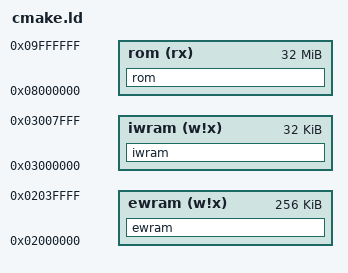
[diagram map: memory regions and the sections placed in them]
ENTRY(__start)

gNumMusicPlayers = 0x20;
gMaxLines = 0;

MEMORY {
    ewram (w!x) : ORIGIN = 0x02000000, LENGTH = 256K
    iwram (w!x) : ORIGIN = 0x03000000, LENGTH = 32K
    rom (rx) : ORIGIN = 0x08000000, LENGTH = 32M
}

SECTIONS {
    ewram (NOLOAD) : ALIGN(4) {
        . = 0x00000006; gUnk_02000006 = .;
        . = 0x00000010; gUnk_02000010 = .;
        . = 0x00000020; gUnk_02000020 = .;
        . = 0x00000030; gUnk_02000030 = .;
        . = 0x00000040; gUnk_02000040 = .;
        . = 0x00000050; gTextBox = .;
        . = 0x0000005C; gUnk_0200005C = .;
        . = 0x00000070; gUnk_02000070 = .;
        . = 0x00000080; gMenu = .;
        . = 0x00000080; gIntroState = .;
        . = 0x00000080; gChooseFileState = .;
        . = 0x00000090; gUnk_02000090 = .;
        . = 0x000000B0; gUnk_020000B0 = .;
        . = 0x000000C0; gUnk_020000C0 = .;
        . = 0x00000CC0; gUnk_02000CC0 = .;
        . = 0x00000D00; gUnk_02000D00 = .;
        . = 0x00001A00; gUnk_02001A00 = .;
        . = 0x00001A3C; gUnk_02001A3C = .;
        . = 0x00001A40; gBG3Buffer = .;
        . = 0x00001B40; gUnk_02001B40 = .;
        . = 0x00002A40; gSave = .;
        . = 0x00002AA0; gUnk_02002AA0 = .;
        . = 0x00002AC0; gUnk_02002AC0 = .;
        . = 0x00002AC8; gUnk_02002AC8 = .;
        . = 0x00002AE8; gStats = .;
        . = 0x00002B0E; gUnk_02002B0E = .;
        . = 0x00002B32; gUnk_02002B32 = .;
        . = 0x00002B54; gUnk_02002B54 = .;
        . = 0x00002B58; gUnk_02002B58 = .;
        . = 0x00002B6B; gUnk_02002B6B = .;
        . = 0x00002C01; gUnk_02002C01 = .;
        . = 0x00002C81; gUnk_02002C81 = .;
        . = 0x00002C8E; gUnk_02002C8E = .;
        . = 0x00002C9C; gGlobalFlags = .;
        . = 0x00002E9C; gUnk_02002E9C = .;
        . = 0x00002ECC; gUnk_02002ECC = .;
        . = 0x00002F00; gMapDataTopSpecial = .;
        . = 0x00006F00; gUnk_02006F00 = .;
        . = 0x0000AF00; gUnk_0200AF00 = .;
        . = 0x0000AF13; gUnk_0200AF13 = .;
        . = 0x0000AF34; gUnk_0200AF34 = .;
        . = 0x0000B240; gUnk_0200B240 = .;
        . = 0x0000B640; gUnk_0200B640 = .;
        . = 0x0000B644; gUsedPalettes = .;
        . = 0x0000B650; gUnk_0200B650 = .;
        . = 0x0000B654; gMapDataTop = .;
        . = 0x0000D654; gUnk_0200D654 = .;
        . = 0x0000E654; gUnk_0200E654 = .;
        . = 0x00010654; gMetatileTypesTop = .;
        . = 0x00011654; gUnk_02011654 = .;
        . = 0x00012654; gMetatilesTop = .;
        . = 0x00016654; gUnk_02016654 = .;
        . = 0x00017654; gUnk_02017654 = .;
        . = 0x00017660; gUnk_02017660 = .;
        . = 0x000176A0; gPaletteBuffer = .;
        . = 0x000176E0; gUnk_020176E0 = .;
        . = 0x00017700; gUnk_02017700 = .;
        . = 0x00017830; gUnk_02017830 = .;
        . = 0x000178E0; gUnk_020178E0 = .;
        . = 0x00017AA0; gUnk_02017AA0 = .;
        . = 0x00017BA0; gUnk_02017BA0 = .;
        . = 0x00018EA0; gUnk_02018EA0 = .;
        . = 0x00018EB0; gUnk_02018EB0 = .;
        . = 0x00018EE0; gUnk_02018EE0 = .;
        . = 0x00019EE0; gUnk_02019EE0 = .;
        . = 0x00019F6C; gUnk_02019F6C = .;
        . = 0x0001AEE0; gUnk_0201AEE0 = .;
        . = 0x00021EE0; gSoundPlayingInfo = .;
        . = 0x00021F00; gUnk_02021F00 = .;
        . = 0x00021F20; gUnk_02021F20 = .;
        . = 0x00021F30; gBG1Buffer = .;
        . = 0x00021F70; gUnk_02021F70 = .;
        . = 0x00022030; gUnk_02022030 = .;
        . = 0x00022130; gUnk_02022130 = .;
        . = 0x00022730; gUnk_02022730 = .;
        . = 0x00022740; gUnk_02022740 = .;
        . = 0x00022750; gPlayerScriptExecutionContext = .;
        . = 0x00022780; gUnk_02022780 = .;
        . = 0x000227DC; gUnk_020227DC = .;
        . = 0x000227E8; gUnk_020227E8 = .;
        . = 0x000227F0; gUnk_020227F0 = .;
        . = 0x000227F8; gUnk_020227F8 = .;
        . = 0x00022800; gUnk_02022800 = .;
        . = 0x0002281E; gUnk_0202281E = .;
        . = 0x00022830; gUnk_02022830 = .;
        . = 0x00024030; gUnk_02024030 = .;
        . = 0x00024048; gUnk_02024048 = .;
        . = 0x00024050; gUnk_02024050 = .;
        . = 0x00024090; gUnk_02024090 = .;
        . = 0x00024490; gUnk_02024490 = .;
        . = 0x00024494; gUnk_02024494 = .;
        . = 0x000246B0; gUnk_020246B0 = .;
        . = 0x00025EB0; gUnk_02025EB0 = .;
        . = 0x00025EB4; gMapDataBottom = .;
        . = 0x00027EB4; gUnk_02027EB4 = .;
        . = 0x00028EB4; gUnk_02028EB4 = .;
        . = 0x0002AEB4; gMetatileTypesBottom = .;
        . = 0x0002BEB4; gUnk_0202BEB4 = .;
        . = 0x0002CEB4; gMetatilesBottom = .;
        . = 0x00030EB4; gUnk_02030EB4 = .;
        . = 0x00031EC0; gUnk_02031EC0 = .;
        . = 0x00032EC0; gUnk_02032EC0 = .;
        . = 0x00032EDC; gUnk_02032EDC = .;
        . = 0x00032F14; gUnk_02032F14 = .;
        . = 0x00033280; gActiveScriptInfo = .;
        . = 0x00033290; gUnk_02033290 = .;
        . = 0x00033A90; gArea = .;
        . = 0x00033AB8; gUnk_02033AB8 = .;
        . = 0x00033ACC; gUnk_02033ACC = .;
        . = 0x000342CC; gUnk_020342CC = .;
        . = 0x000342F8; gUnk_020342F8 = .;
        . = 0x00034330; gUnk_02034330 = .;
        . = 0x00034350; gRoomVars = .;
        . = 0x00034364; gRoomFlags = .;
        . = 0x00034398; gUnk_02034398 = .;
        . = 0x00034480; gUnk_02034480 = .;
        . = 0x00034490; gUnk_02034490 = .;
        . = 0x00034492; gUnk_02034492 = .;
        . = 0x000344A0; gUnk_020344A0 = .;
        . = 0x000344B0; gBG2Buffer = .;
        . = 0x000344F0; gUnk_020344F0 = .;
        . = 0x00034CB0; gBG0Buffer = .;
        . = 0x00034CB2; gUnk_02034CB2 = .;
        . = 0x00034CF0; gUnk_02034CF0 = .;
        . = 0x00034D30; gUnk_02034D30 = .;
        . = 0x00034DF0; gUnk_02034DF0 = .;
        . = 0x000350E2; gUnk_020350E2 = .;
        . = 0x000350F0; gUnk_020350F0 = .;
        . = 0x00035160; gUnk_02035160 = .;
        . = 0x000354B0; gUnk_020354B0 = .;
        . = 0x000354B4; gManagerCount = .;
        . = 0x000354C0; gUnk_020354C0 = .;
        . = 0x0003553E; gUnk_0203553E = .;
        . = 0x00035540; gzHeap = .;
        . = 0x00035542; gUnk_02035542 = .;
        . = 0x00036540; gUnk_02036540 = .;
        . = 0x00036570; gScriptExecutionContextArray = .;
        . = 0x000369F0; gUnk_020369F0 = .;
        . = 0x00036A38; gUnk_02036A38 = .;
        . = 0x00036A40; gUnk_02036A40 = .;
        . = 0x00036A50; gEEPROMConfig = .;
        . = 0x00036A58; gUnk_02036A58 = .;
        . = 0x00036AD8; gUnk_02036AD8 = .;
        . = 0x00036BB8; gUnk_02036BB8 = .;
        . = 0x00036BC0; gMPlayTracks = .;
        . = 0x00038560; gUnk_02038560 = .;
        . = 0x00040000;
    } >ewram

    iwram (NOLOAD) : ALIGN(4) {
        . = 0x00000000; gUnk_03000000 = .;
        . = 0x00000020; gUnk_03000020 = .;
        . = 0x00000420; gUnk_03000420 = .;
        . = 0x00000B80; gUnk_03000B80 = .;
        . = 0x00000BD4; gUnk_03000BD4 = .;
        . = 0x00000BF0; gRoomControls = .;
        . = 0x00000BF6; gUnk_03000BF6 = .;
        . = 0x00000BF8; gUnk_03000BF8 = .;
        . = 0x00000C24; gUnk_03000C24 = .;
        . = 0x00000C30; gUnk_03000C30 = .;
        . = 0x00000E10; gUnk_03000E10 = .;
        . = 0x00000F50; gScreen = .;
        . = 0x00000F58; gBG0Settings = .;
        . = 0x00000F64; gBG1Settings = .;
        . = 0x00000F70; gBGAffSettings = .;
        . = 0x00000F88; gBgControls = .;
        . = 0x00000FBC; gUnk_03000FBC = .;
        . = 0x00000FD0; gFadeControl = .;
        . = 0x00000FF0; gInput = .;
        . = 0x00001000; gMain = .;
        . = 0x00001010; gOamCmd = .;
        . = 0x00001020; gUnk_03001020 = .;
        . = 0x000010A0; gScreenTransition = .;
        . = 0x000010AC; gUnk_030010AC = .;
        . = 0x000010D8; gUnk_030010D8 = .;
        . = 0x000010EC; gUnk_030010EC = .;
        . = 0x0000110C; gUnk_0300110C = .;
        . = 0x00001150; gRand = .;
        . = 0x00001160; gPlayerEntity = .;
        . = 0x00001198; gUnk_03001198 = .;
        . = 0x000011E8; gUnk_030011E8 = .;
        . = 0x000015A0; gUnk_030015A0 = .;
        . = 0x00003BE0; gUnk_03003BE0 = .;
        . = 0x00003C70; gUnk_03003C70 = .;
        . = 0x00003D68; gUnk_03003D68 = .;
        . = 0x00003D70; gEntityLists = .;
        . = 0x00003D80; gUnk_03003D80 = .;
        . = 0x00003D90; gUnk_03003D90 = .;
        . = 0x00003DA0; gUnk_03003DA0 = .;
        . = 0x00003DA8; gUnk_03003DA8 = .;
        . = 0x00003DB0; gUnk_03003DB0 = .;
        . = 0x00003DB8; gHitboxCount = .;
        . = 0x00003DBC; gEntCount = .;
        . = 0x00003DC0; gUnk_03003DC0 = .;
        . = 0x00003DD0; gUnk_03003DD0 = .;
        . = 0x00003DE0; gUnk_03003DE0 = .;
        . = 0x00003DE4; gUnk_03003DE4 = .;
        . = 0x00003DF0; gUnk_03003DF0 = .;
        . = 0x00003DF8; gUnk_03003DF8 = .;
        . = 0x00003F80; gPlayerState = .;
        . = 0x00003FC0; gUnk_03003FC0 = .;
        . = 0x00004010; gUnk_03004010 = .;
        . = 0x00004020; gUnk_03004020 = .;
        . = 0x00004030; gUnk_03004030 = .;
        . = 0x00004040; gUnk_03004040 = .;
        . = 0x0000404C; SoundMainRAM_Buffer = .;
        . = 0x0000404D; gUnk_0300404D = .;
        . = 0x000043D0; gSoundInfo = .;
        . = 0x00004D50; gMPlayJumpTable = .;
        . = 0x00004D54; gUnk_03004D54 = .;
        . = 0x00004DD8; gUnk_03004DD8 = .;
        . = 0x00004DDC; gUnk_03004DDC = .;
        . = 0x00004DE0; gCgbChans = .;
        . = 0x00004EE0; gMPlayInfos = .;
        . = 0x000055E0; gMPlayMemAccArea = .;
        . = 0x000055F0; gMPlayInfos2 = .;
        . = 0x000056F0; gUnk_030056F0 = .;
        . = 0x000056F1; gUnk_030056F1 = .;
        . = 0x00005740; gUnk_03005740 = .;
        . = 0x0000574C; gUnk_0300574C = .;
        . = 0x00005760; gUnk_03005760 = .;
        . = 0x00005770; gUnk_03005770 = .;
        . = 0x00005778; gUnk_03005778 = .;
        . = 0x00005780; gUnk_03005780 = .;
        . = 0x0000579C; gUnk_0300579C = .;
        . = 0x000057A8; gUnk_030057A8 = .;
        . = 0x000057BC; gUnk_030057BC = .;
        . = 0x000057CC; gUnk_030057CC = .;
        . = 0x000057D4; gUnk_030057D4 = .;
        . = 0x00005800; gUnk_03005800 = .;
        . = 0x0000581C; gUnk_0300581C = .;
        . = 0x00005828; gUnk_03005828 = .;
        . = 0x0000583C; gUnk_0300583C = .;
        . = 0x0000584C; gUnk_0300584C = .;
        . = 0x00005854; gUnk_03005854 = .;
        . = 0x00005864; gUnk_03005864 = .;
        . = 0x00005880; gUnk_03005880 = .;
        . = 0x0000588C; gUnk_0300588C = .;
        . = 0x000058A0; gUnk_030058A0 = .;
        . = 0x000058B0; gUnk_030058B0 = .;
        . = 0x000058B8; gUnk_030058B8 = .;
        . = 0x000058C8; gUnk_030058C8 = .;
        . = 0x000058DC; gUnk_030058DC = .;
        . = 0x000058F8; gUnk_030058F8 = .;
        . = 0x00005918; gUnk_03005918 = .;
        . = 0x000059F0; gDoCollision = .;
        . = 0x00005CA4; gUnk_03005CA4 = .;
        . = 0x00005CD0; gUnk_03005CD0 = .;
        . = 0x00005CFC; gUnk_03005CFC = .;
        . = 0x00005D18; gUnk_03005D18 = .;
        . = 0x00005D24; gUnk_03005D24 = .;
        . = 0x00005D58; gUnk_03005D58 = .;
        . = 0x00005D5C; gUnk_03005D5C = .;
        . = 0x00005D90; IntrMain = .;
        . = 0x00005E60; gUnk_03005E60 = .;
        . = 0x00005E98; gUnk_03005E98 = .;
        . = 0x00005F24; _EntUpdate = .;
        . = 0x00005F40; gUnk_03005F40 = .;
        . = 0x00005FBC; gUnk_03005FBC = .;
        . = 0x00005FF0; gUnk_03005FF0 = .;
        . = 0x000060F0; gUnk_030060F0 = .;
        . = 0x00006164; gUnk_03006164 = .;
        . = 0x00006580; gUnk_03006580 = .;
        . = 0x0000659C; gUnk_0300659C = .;
        . = 0x000067E4; gUnk_030067E4 = .;
        . = 0x000068CC; gUnk_030068CC = .;
        . = 0x0000694C; gUnk_0300694C = .;
        . = 0x0000695C; gUnk_0300695C = .;
        . = 0x00007F00; gUnk_03007F00 = .;
        . = 0x00007FA0; gUnk_03007FA0 = .;
        . = 0x00007FFA; gUnk_03007FFA = .;
        . = 0x00008000;
    } >iwram

    rom : ALIGN(2) {

        /* handwritten assembly */
        asm/crt0.s.obj(.text);
        asm/code_08000108.s.obj(.text);
        data/data_08000360.s.obj(.rodata);
        asm/code_08000E44.s.obj(.text);
        asm/libgcc.s.obj(.text);
        asm/code_08000F10.s.obj(.text);
        data/data_08000F54.s.obj(.rodata);
        asm/code_080011C4.s.obj(.text);
        data/data_080029B4.s.obj(.rodata);
        asm/code_08003FC4.s.obj(.text);
        asm/code_080043E8.s.obj(.text);
        data/data_08007DF4.s.obj(.rodata);
        asm/code_0800857C.s.obj(.text);
        /* scripts */
        data/scripts.s.obj(.text);
        asm/code_08016984.s.obj(.text);
        asm/sub_08016AE4.s.obj(.text);


        /* C source compiled with interworking */
        asm/code_08016B30.s.obj(.text);
        asm/updateBackgroundRegisters.s.obj(.text);
        src/arm_proxy.c.obj(.text);
        asm/code_08016DF8.s.obj(.text);
        /* C source compiled without interworking */
        asm/code_08018500.s.obj(.text);
        src/code_08018C58.c.obj(.text);
        src/playerItem/playerItem11.c.obj(.text);
        asm/playerItem11.s.obj(.text);
        src/playerItem/playerItemBow.c.obj(.text);
        asm/playerItem/playerItemBow.s.obj(.text);
        asm/playerItem/playerItemSwordBeam.s.obj(.text);
        asm/code_0801967C.s.obj(.text);
        asm/playerItem/playerItemBomb.s.obj(.text);
        asm/playerItem/playerItem3.s.obj(.text);
        asm/playerItem/playerItemC.s.obj(.text);
        asm/playerItem/playerItemSwordSpin.s.obj(.text);
        asm/playerItemCellOverwriteSet.s.obj(.text);
        asm/code_0801C1D4.s.obj(.text);
        asm/drawUI.s.obj(.text);
        asm/code_0801C370.s.obj(.text);
        asm/drawRupees.s.obj(.text);
        asm/code_0801C5E0.s.obj(.text);
        asm/drawHealth.s.obj(.text);
        asm/sub_0801C824.s.obj(.text);
        asm/code_0801C85C.s.obj(.text);
        src/ezloNag.c.obj(.text);
        asm/code_0801CEC0.s.obj(.text);
        src/utils.c.obj(.text);
        asm/code_0801D79C.s.obj(.text);
        /* enemies */
        src/enemy/octorok.c.obj(.text);
        src/enemy/chuchu.c.obj(.text);
        src/enemy/leever.c.obj(.text);
        src/enemy/peahat.c.obj(.text);
        src/enemy/rollobite.c.obj(.text);
        src/enemy/darkNut.c.obj(.text);
        src/enemy/hangingSeed.c.obj(.text);
        src/enemy/beetle.c.obj(.text);
        src/enemy/keese.c.obj(.text);
        src/enemy/doorMimic.c.obj(.text);
        src/enemy/rockChuchu.c.obj(.text);
        src/enemy/spinyChuchu.c.obj(.text);
        src/enemy/cuccoChickAggr.c.obj(.text);
        src/enemy/moldorm.c.obj(.text);
        src/enemy/enemyE.c.obj(.text);
        src/enemy/moldworm.c.obj(.text);
        src/enemy/sluggula.c.obj(.text);
        src/enemy/pesto.c.obj(.text);
        src/enemy/puffstool.c.obj(.text);
        src/enemy/chuchuBoss.c.obj(.text);
        asm/chuchuBoss.s.obj(.text);
        src/enemy/likeLike.c.obj(.text);
        src/enemy/spearMoblin.c.obj(.text);
        src/enemy/businessScrub.c.obj(.text);
        src/enemy/rupeeLike.c.obj(.text);
        src/enemy/madderpillar.c.obj(.text);
        src/enemy/waterDrop.c.obj(.text);
        src/enemy/wallMaster.c.obj(.text);
        src/enemy/bombPeahat.c.obj(.text);
        src/enemy/spark.c.obj(.text);
        src/enemy/chaser.c.obj(.text);
        src/enemy/spikedBeetle.c.obj(.text);
        src/enemy/sensorBladeTrap.c.obj(.text);
        src/enemy/helmasaur.c.obj(.text);
        src/enemy/fallingBoulder.c.obj(.text);
        src/enemy/bobomb.c.obj(.text);
        src/enemy/wallMaster2.c.obj(.text);
        asm/gleerok.s.obj(.text);
        asm/vaatiEyesMacro.s.obj(.text);
        src/enemy/tektite.c.obj(.text);
        asm/wizzrobeWind.s.obj(.text);
        asm/wizzrobeFire.s.obj(.text);
        asm/wizzrobeIce.s.obj(.text);
        src/code_080300AC.c.obj(.text); /* ??? */
        asm/code_080300AC.s.obj(.text); /* ??? */
        asm/armos.s.obj(.text);
        asm/eyegore.s.obj(.text);
        src/enemy/rope.c.obj(.text);
        src/enemy/smallPesto.c.obj(.text);
        src/enemy/acroBandits.c.obj(.text);
        src/enemy/bladeTrap.c.obj(.text);
        src/enemy/keaton.c.obj(.text);
        asm/crow.s.obj(.text);
        asm/mulldozer.s.obj(.text);
        asm/bombarossa.s.obj(.text);
        src/enemy/wisp.c.obj(.text);
        asm/spinyBeetle.s.obj(.text);
        asm/mazaalHead.s.obj(.text);
        asm/mazaalMacro.s.obj(.text);
        asm/mazaalHand.s.obj(.text);
        asm/octorokBoss.s.obj(.text);
        asm/flyingPot.s.obj(.text);
        src/enemy/gibdo.c.obj(.text);
        asm/octorokGolden.s.obj(.text);
        src/enemy/tektiteGolden.c.obj(.text);
        src/enemy/ropeGolden.c.obj(.text);
        asm/cloudPiranha.s.obj(.text);
        asm/scissorsBeetle.s.obj(.text);
        asm/cuccoAggr.s.obj(.text);
        asm/stalfos.s.obj(.text);
        asm/flyingSkull.s.obj(.text);
        asm/mazaalBracelet.s.obj(.text);
        asm/takkuri.s.obj(.text);
        src/enemy/bowMoblin.c.obj(.text);
        asm/bowMoblin.s.obj(.text);
        src/enemy/lakitu.c.obj(.text);
        src/enemy/lakituCloud.c.obj(.text);
        asm/enemy49.s.obj(.text);
        asm/vaatiRebornEnemy.s.obj(.text);
        asm/vaatiProjectile.s.obj(.text);
        asm/ballChainSoldier.s.obj(.text);
        src/enemy/enemy4D.c.obj(.text);
        asm/enemy4D.s.obj(.text);
        asm/ghini.s.obj(.text);
        asm/vaatiTransfigured.s.obj(.text);
        asm/enemy50.s.obj(.text);
        asm/vaatiWrath.s.obj(.text);
        asm/vaatiArm.s.obj(.text);
        asm/dust.s.obj(.text);
        src/enemy/vaatiBall.c.obj(.text);
        src/enemy/slime.c.obj(.text);
        asm/sub_080451CC.s.obj(.text);
        src/enemy/miniSlime.c.obj(.text);
        src/enemy/fireballGuy.c.obj(.text);
        src/enemy/miniFireballGuy.c.obj(.text);
        asm/enemy5A.s.obj(.text);
        asm/businessScrubPrologue.s.obj(.text);
        asm/gyorgFemale.s.obj(.text);
        src/enemy/gyorgMale.c.obj(.text);
        asm/curtain.s.obj(.text);
        asm/enemy5F.s.obj(.text);
        asm/gyorgChild.s.obj(.text);
        asm/gyorgFemaleEye.s.obj(.text);
        asm/enemy62.s.obj(.text);
        asm/gyorgFemaleMouth.s.obj(.text);
        asm/enemy64.s.obj(.text);
        src/enemy/treeItem.c.obj(.text);
        asm/enemy66.s.obj(.text);
        /* END enemies */
        src/code_08049CD4.c.obj(.text);
        asm/code_08049D30.s.obj(.text);
        asm/sub_0804AA30.s.obj(.text);
        src/createEnemy.c.obj(.text);
        src/code_0804AA84.c.obj(.text);
        asm/code_0804AA84.s.obj(.text);
        src/loadRoomEntityList.c.obj(.text);
        asm/loadRoomEntity.s.obj(.text);
        asm/code_0804AEB0.s.obj(.text);
        src/loadRoom.c.obj(.text);
        asm/code_0804B058.s.obj(.text);
        src/room.c.obj(.text);
        asm/code_0804B9F8.s.obj(.text);
        src/sub_08050008.c.obj(.text);
        src/fade.c.obj(.text);
        asm/code_08050038.s.obj(.text);
        src/fileScreen.c.obj(.text);
        asm/fileScreen.s.obj(.text);
        src/game.c.obj(.text);
        asm/code_080526F8.s.obj(.text);
        asm/modBombs.s.obj(.text);
        asm/modArrows.s.obj(.text);
        src/code_0805436C.c.obj(.text);
        asm/code_0805436C.s.obj(.text);
        asm/playerItem/playerItemLantern.s.obj(.text);
        asm/code_08054C04.s.obj(.text);
        src/sub_08055E08.c.obj(.text);
        src/main.c.obj(.text);
        src/textbox.c.obj(.text);
        asm/code_08056418.s.obj(.text);
        src/manager/manager1.c.obj(.text);
        asm/manager1.s.obj(.text);
        src/manager/manager2.c.obj(.text);
        asm/manager2.s.obj(.text);
        src/manager/manager3.c.obj(.text);
        src/manager/manager4.c.obj(.text);
        src/manager/manager5.c.obj(.text);
        src/manager/manager6.c.obj(.text);
        src/manager/manager7.c.obj(.text);
        src/manager/manager8.c.obj(.text);
        src/manager/manager9.c.obj(.text);
        src/manager/managerA.c.obj(.text);
        src/manager/managerB.c.obj(.text);
        src/manager/managerC.c.obj(.text);
        asm/managerD.s.obj(.text);
        src/manager/managerE.c.obj(.text);
        asm/managerF.s.obj(.text);
        asm/manager10.s.obj(.text);
        asm/manager11.s.obj(.text);
        asm/manager12.s.obj(.text);
        asm/manager13.s.obj(.text);
        asm/manager14.s.obj(.text);
        src/manager/manager15.c.obj(.text);
        asm/manager16.s.obj(.text);
        asm/manager17.s.obj(.text);
        asm/manager18.s.obj(.text);
        asm/manager19.s.obj(.text);
        src/manager/manager1A.c.obj(.text);
        asm/manager1B.s.obj(.text);
        asm/manager1C.s.obj(.text);
        asm/manager1D.s.obj(.text);
        src/manager/manager1E.c.obj(.text);
        asm/manager1F.s.obj(.text);
        src/manager/manager20.c.obj(.text);
        asm/manager21.s.obj(.text);
        asm/manager22.s.obj(.text);
        asm/manager23.s.obj(.text);
        asm/manager24.s.obj(.text);
        asm/manager25.s.obj(.text);
        src/manager/manager26.c.obj(.text);
        src/manager/manager27.c.obj(.text);
        src/manager/manager28.c.obj(.text);
        asm/manager29.s.obj(.text);
        asm/manager2A.s.obj(.text);
        asm/manager2B.s.obj(.text);
        asm/manager2C.s.obj(.text);
        asm/manager2D.s.obj(.text);
        src/manager/manager2E.c.obj(.text);
        asm/manager2E.s.obj(.text);
        asm/manager2F.s.obj(.text);
        src/manager/manager30.c.obj(.text);
        asm/manager31.s.obj(.text);
        asm/manager32.s.obj(.text);
        asm/manager33.s.obj(.text);
        asm/manager34.s.obj(.text);
        asm/manager35.s.obj(.text);
        asm/manager36.s.obj(.text);
        asm/manager37.s.obj(.text);
        asm/manager38.s.obj(.text);
        src/manager/manager39.c.obj(.text);
        asm/sub_0805E248.s.obj(.text);
        src/sub_0805E374.c.obj(.text);
        src/sub_0805E3A0.c.obj(.text);
        asm/code_0805E3B0.s.obj(.text);
        asm/getEmptyEntity.s.obj(.text);
        src/entity.c.obj(.text);
        src/code_0805EC04.c.obj(.text);
        asm/code_0805EC04.s.obj(.text);
        src/code_0805F9A0.c.obj(.text);
        src/debugScreen.c.obj(.text);
        src/playerItem/playerItem14.c.obj(.text);
        /* npcs */
        src/npc/gentari.c.obj(.text);
        src/npc/festari.c.obj(.text);
        asm/festari.s.obj(.text);
        src/npc/forestMinish.c.obj(.text);
        src/npc/postman.c.obj(.text);
        asm/postman.s.obj(.text);
        asm/npc5.s.obj(.text);
        src/npc/townsperson.c.obj(.text);
        asm/kid.s.obj(.text);
        src/npc/npc9.c.obj(.text);
        src/npc/stamp.c.obj(.text);
        asm/marcy.s.obj(.text);
        src/npc/wheaton.c.obj(.text);
        asm/pita.s.obj(.text);
        asm/minishEzlo.s.obj(.text);
        src/npc/mailbox.c.obj(.text);
        src/npc/beedle.c.obj(.text);
        asm/brocco.s.obj(.text);
        asm/sittingPerson.s.obj(.text);
        asm/pina.s.obj(.text);
        src/npc/guard.c.obj(.text);
        asm/guardWithSpear.s.obj(.text);
        asm/castleMaid.s.obj(.text);
        asm/din.s.obj(.text);
        asm/nayru.s.obj(.text);
        asm/farore.s.obj(.text);
        asm/sturgeon.s.obj(.text);
        src/npc/tingleSiblings.c.obj(.text);
        asm/tingleSiblings.s.obj(.text);
        asm/stockwell.s.obj(.text);
        src/npc/talon.c.obj(.text);
        src/npc/malon.c.obj(.text);
        src/npc/epona.c.obj(.text);
        src/npc/milkCart.c.obj(.text);
        asm/ghostBrothers.s.obj(.text);
        src/npc/smith.c.obj(.text);
        asm/npc23.s.obj(.text);
        asm/kingDaltus.s.obj(.text);
        asm/ministerPotho.s.obj(.text);
        asm/npc26.s.obj(.text);
        asm/vaati.s.obj(.text);
        src/npc/zelda.c.obj(.text);
        src/npc/mutoh.c.obj(.text);
        src/npc/carpenter.c.obj(.text);
        asm/carpenter.s.obj(.text);
        asm/castorWildsStatue.s.obj(.text);
        asm/npc/cat.s.obj(.text);
        src/npc/cat.c.obj(.text);
        asm/cat.s.obj(.text);
        asm/mountainMinish.s.obj(.text);
        src/npc/zeldaFollower.c.obj(.text);
        asm/zeldaFollower.s.obj(.text);
        src/npc/melari.c.obj(.text);
        src/npc/bladeBrothers.c.obj(.text);
        src/npc/cow.c.obj(.text);
        src/npc/goron.c.obj(.text);
        src/npc/goronMerchant.c.obj(.text);
        asm/goronMerchant.s.obj(.text);
        asm/gorman.s.obj(.text);
        asm/dog.s.obj(.text);
        src/npc/syrup.c.obj(.text);
        asm/syrup.s.obj(.text);
        src/npc/rem.c.obj(.text);
        asm/rem.s.obj(.text);
        src/npc/townMinish.c.obj(.text);
        src/npc/librari.c.obj(.text);
        src/npc/percy.c.obj(.text);
        asm/percy.s.obj(.text);
        asm/vaatiReborn.s.obj(.text);
        src/npc/moblinLady.c.obj(.text);
        asm/librarians.s.obj(.text);
        asm/farmers.s.obj(.text);
        src/npc/carlov.c.obj(.text);
        src/npc/dampe.c.obj(.text);
        asm/drLeft.s.obj(.text);
        asm/kingGustaf.s.obj(.text);
        asm/gina.s.obj(.text);
        src/npc/simon.c.obj(.text);
        src/npc/anju.c.obj(.text);
        asm/mama.s.obj(.text);
        src/npc/emma.c.obj(.text);
        src/npc/teachers.c.obj(.text);
        src/npc/windTribespeople.c.obj(.text);
        asm/windTribespeople.s.obj(.text);
        asm/gregal.s.obj(.text);
        src/npc/mayorHagen.c.obj(.text);
        src/npc/bigGoron.c.obj(.text);
        asm/bigGoron.s.obj(.text);
        src/npc/ezloCap.c.obj(.text);
        asm/npc4E.s.obj(.text);
        src/npc/clothesRack.c.obj(.text);
        asm/clothesRack.s.obj(.text);
        asm/picolyteBottles.s.obj(.text);
        asm/smallTownMinish.s.obj(.text);
        asm/hurdyGurdyMan.s.obj(.text);
        asm/cucco.s.obj(.text);
        asm/cuccoChick.s.obj(.text);
        asm/fusionMenuNPC.s.obj(.text);
        asm/phonograph.s.obj(.text);
        asm/npc58.s.obj(.text);
        /* END npcs */
        asm/code_0806EC20.s.obj(.text);
        src/createNPC.c.obj(.text);
        asm/code_0806ED78.s.obj(.text);
        src/coord.c.obj(.text);
        asm/code_0806FA6C.s.obj(.text);
        asm/playerItem/playerItem12.s.obj(.text);
        asm/playerItem/playerItemPacciCane.s.obj(.text);
        asm/code_0807059C.s.obj(.text);
        src/player.c.obj(.text);
        asm/code_08070698.s.obj(.text);
        asm/stairsInteract.s.obj(.text);
        asm/code_080732D0.s.obj(.text);
        asm/item/itemDebug.s.obj(.text);
        asm/item/itemSword.s.obj(.text);
        asm/item/itemLantern.s.obj(.text);
        asm/item/itemBoomerang.s.obj(.text);
        asm/item/itemBow.s.obj(.text);
        asm/item/itemBomb.s.obj(.text);
        asm/item/itemTryPickupObject.s.obj(.text);
        asm/item/itemRocsCape.s.obj(.text);
        asm/item/itemPegasusBoots.s.obj(.text);
        asm/code_080732D0.s.obj(.text);
        asm/ocarina.s.obj(.text);
        src/item/itemPacciCane.c.obj(.text);
        src/item/itemShield.c.obj(.text);
        src/item/itemGustJar.c.obj(.text);
        asm/item/itemGustJar.s.obj(.text);
        asm/item/itemMoleMitts.s.obj(.text);
        asm/item/itemJarEmpty.s.obj(.text);
        asm/code_08077698.s.obj(.text);
        asm/respawnPlayer.s.obj(.text);
        src/code_08077B98.c.obj(.text);
        src/code_08077DF4.c.obj(.text);
        asm/code_08077B98.s.obj(.text);
        src/code_08078778.c.obj(.text);
        asm/code_08078778.s.obj(.text);
        src/sub_0807B820.c.obj(.text);
        asm/code_0807B9B8.s.obj(.text);
        src/sub_0807C998.c.obj(.text);
        asm/sub_0807CA18.s.obj(.text);
        asm/getInventoryValue.s.obj(.text);
        asm/code_0807CAA0.s.obj(.text);
        src/flags.c.obj(.text);
        src/save.c.obj(.text);
        src/code_0807CC3C.c.obj(.text);
        src/script.c.obj(.text);
        asm/code_0807F0D8.s.obj(.text);
        src/code_0808091C.c.obj(.text);
        asm/code_0808091C.s.obj(.text);
        /* objects */
        src/object/itemOnGround.c.obj(.text);
        asm/deathFx.s.obj(.text);
        asm/itemForSale.s.obj(.text);
        src/object/button.c.obj(.text);
        asm/object4.s.obj(.text);
        src/object/pot.c.obj(.text);
        asm/object6.s.obj(.text);
        asm/blockPushed.s.obj(.text);
        asm/lockedDoor.s.obj(.text);
        asm/object9.s.obj(.text);
        src/object/objectA.c.obj(.text);
        asm/objectB.s.obj(.text);
        src/object/chestSpawner.c.obj(.text);
        asm/chestSpawner.s.obj(.text);
        asm/objectD.s.obj(.text);
        asm/objectE.s.obj(.text);
        asm/specialFx.s.obj(.text);
        asm/object10.s.obj(.text);
        asm/object11.s.obj(.text);
        asm/object12.s.obj(.text);
        src/object/railtrack.c.obj(.text);
        asm/lilypadLarge.s.obj(.text);
        asm/object15.s.obj(.text);
        asm/floatingPlatform.s.obj(.text);
        asm/object17.s.obj(.text);
        asm/evilSpirit.s.obj(.text);
        src/object/houseDoorExterior.c.obj(.text);
        src/object/object1A.c.obj(.text);
        src/object/greatFairy.c.obj(.text);
        src/object/object1C.c.obj(.text);
        src/object/object1D.c.obj(.text);
        asm/object1E.s.obj(.text);
        asm/object1F.s.obj(.text);
        asm/object20.s.obj(.text);
        asm/object21.s.obj(.text);
        asm/figurineDevice.s.obj(.text);
        asm/eyeSwitch.s.obj(.text);
        asm/object24.s.obj(.text);
        asm/bigBarrel.s.obj(.text);
        asm/object26.s.obj(.text);
        asm/pushableStatue.s.obj(.text);
        asm/object28.s.obj(.text);
        asm/object29.s.obj(.text);
        src/object/object2A.c.obj(.text);
        asm/object2A.s.obj(.text);
        asm/object2B.s.obj(.text);
        asm/beanstalk.s.obj(.text);
        src/object/smoke.c.obj(.text);
        asm/pushableRock.s.obj(.text);
        asm/hittableLever.s.obj(.text);
        asm/object30.s.obj(.text);
        asm/object31.s.obj(.text);
        asm/pullableMushroom.s.obj(.text);
        asm/bollard.s.obj(.text);
        asm/warpPoint.s.obj(.text);
        asm/object35.s.obj(.text);
        asm/object36.s.obj(.text);
        asm/object37.s.obj(.text);
        asm/jarPortal.s.obj(.text);
        asm/bossDoor.s.obj(.text);
        asm/object3A.s.obj(.text);
        asm/macroMushroomStalks.s.obj(.text);
        asm/object75.s.obj(.text); /* 75 and 76 are mislocated in base game */
        asm/object76.s.obj(.text);
        asm/code_0808C964.s.obj(.text);
        asm/macroPlayer.s.obj(.text);
        asm/object3D.s.obj(.text);
        asm/object3E.s.obj(.text);
        src/object/giantLeaf.c.obj(.text);
        asm/fairy.s.obj(.text);
        asm/ladderUp.s.obj(.text);
        asm/object42.s.obj(.text);
        asm/object43.s.obj(.text);
        asm/object44.s.obj(.text);
        asm/object45.s.obj(.text);
        asm/giantBookLadder.s.obj(.text);
        src/object/heartContainer.c.obj(.text);
        src/object/fileScreenObjects.c.obj(.text);
        src/object/object49.c.obj(.text);
        src/object/backgroundCloud.c.obj(.text);
        asm/object4B.s.obj(.text);
        asm/pushableFurniture.s.obj(.text);
        asm/furniture.s.obj(.text);
        src/object/minishSizedEntrance.c.obj(.text);
        src/object/archway.c.obj(.text);
        asm/giantRock.s.obj(.text);
        asm/object51.s.obj(.text);
        asm/object52.s.obj(.text);
        asm/object53.s.obj(.text);
        asm/pullableLever.s.obj(.text);
        src/object/minecart.c.obj(.text);
        asm/minecart.s.obj(.text);
        src/object/thoughtBubble.c.obj(.text);
        src/object/hiddenLadderDown.c.obj(.text);
        asm/gentariCurtains.s.obj(.text);
        asm/lavaPlatform.s.obj(.text);
        asm/object5A.s.obj(.text);
        asm/object5B.s.obj(.text);
        src/object/mask.c.obj(.text);
        asm/houseDoorInterior.s.obj(.text);
        asm/whirlwind.s.obj(.text);
        asm/objectBlockingStairs.s.obj(.text);
        src/object/swordsmanNewsletter.c.obj(.text);
        asm/object61.s.obj(.text);
        asm/giantTwig.s.obj(.text);
        asm/object63.s.obj(.text);
        asm/object64.s.obj(.text);
        asm/ladderHoleInBookshelf.s.obj(.text);
        asm/object66.s.obj(.text);
        asm/object67.s.obj(.text);
        asm/object68.s.obj(.text);
        asm/object69.s.obj(.text);
        asm/object6A.s.obj(.text);
        asm/crenalBeanSprout.s.obj(.text);
        asm/minecartDoor.s.obj(.text);
        asm/objectOnPillar.s.obj(.text);
        src/object/mineralWaterSource.c.obj(.text);
        src/object/minishSizedArchway.c.obj(.text);
        asm/object70.s.obj(.text);
        asm/pushableGrave.s.obj(.text);
        asm/object72.s.obj(.text);
        src/object/lilypadSmall.c.obj(.text);
        asm/object74.s.obj(.text);
        src/object/bell.c.obj(.text);
        asm/macroDecorations.s.obj(.text);
        asm/object79.s.obj(.text);
        asm/steam.s.obj(.text);
        asm/pushableLever.s.obj(.text);
        asm/macroShoes.s.obj(.text);
        asm/objectOnSpinyBeetle.s.obj(.text);
        src/object/object7E.c.obj(.text);
        asm/picoBloom.s.obj(.text);
        asm/object80.s.obj(.text);
        asm/object81.s.obj(.text);
        src/object/bigVortex.c.obj(.text);
        asm/bigPushableLever.s.obj(.text);
        asm/smallIceBlock.s.obj(.text);
        asm/bigIceBlock.s.obj(.text);
        src/object/object86.c.obj(.text);
        asm/object87.s.obj(.text);
        asm/macroBook.s.obj(.text);
        asm/object89.s.obj(.text);
        asm/object8A.s.obj(.text);
        asm/object8B.s.obj(.text);
        asm/book.s.obj(.text);
        asm/fireplace.s.obj(.text);
        asm/object8E.s.obj(.text);
        asm/frozenWaterElement.s.obj(.text);
        asm/object90.s.obj(.text);
        asm/object91.s.obj(.text);
        src/object/bakerOven.c.obj(.text);
        asm/object93.s.obj(.text);
        src/object/windTribeFlag.c.obj(.text);
        src/object/bird.c.obj(.text);
        asm/bird.s.obj(.text);
        asm/object96.s.obj(.text);
        asm/object97.s.obj(.text);
        asm/object98.s.obj(.text);
        asm/object99.s.obj(.text);
        asm/macroAcorn.s.obj(.text);
        asm/object9B.s.obj(.text);
        src/object/treeHidingPortal.c.obj(.text);
        asm/treeHidingPortal.s.obj(.text);
        src/object/lightableSwitch.c.obj(.text);
        src/object/object9E.c.obj(.text);
        src/object/fan.c.obj(.text);
        asm/fan.s.obj(.text);
        asm/objectA0.s.obj(.text);
        src/object/palaceArchway.c.obj(.text);
        src/object/objectA2.c.obj(.text);
        src/object/cloud.c.obj(.text);
        src/object/minishLight.c.obj(.text);
        asm/objectA5.s.obj(.text);
        asm/objectA6.s.obj(.text);
        asm/objectA7.s.obj(.text);
        src/object/objectA8.c.obj(.text);
        asm/objectA8.s.obj(.text);
        asm/objectA9.s.obj(.text);
        asm/waterfallOpening.s.obj(.text);
        asm/objectAB.s.obj(.text);
        asm/fourElements.s.obj(.text);
        asm/objectAD.s.obj(.text);
        src/object/floatingBlock.c.obj(.text);
        src/object/objectAF.c.obj(.text);
        src/object/metalDoor.c.obj(.text);
        src/object/jailBars.c.obj(.text);
        src/object/objectB2.c.obj(.text);
        asm/objectB3.s.obj(.text);
        asm/objectB4.s.obj(.text);
        asm/objectB5.s.obj(.text);
        asm/objectB6.s.obj(.text);
        src/object/well.c.obj(.text);
        asm/windTribeTeleporter.s.obj(.text);
        asm/objectB9.s.obj(.text);
        asm/objectBA.s.obj(.text);
        src/object/windcrest.c.obj(.text);
        asm/litArea.s.obj(.text);
        asm/objectBD.s.obj(.text);
        src/object/pinwheel.c.obj(.text);
        asm/objectBF.s.obj(.text);
        asm/enemyItem.s.obj(.text);
        asm/objectC1.s.obj(.text);
        /* END objects */
        asm/sub_080A276C.s.obj(.text);
        asm/sub_080A2838.s.obj(.text);
        asm/sub_080A285C.s.obj(.text);
        src/createObject.c.obj(.text);
        asm/code_080A29BC.s.obj(.text);
        asm/playerItem/playerItemShield.s.obj(.text);
        asm/playerItem/playerItem15.s.obj(.text);
        src/audio.c.obj(.text);
        asm/code_080A3480.s.obj(.text);
        src/sub_080A3B84.c.obj(.text);
        asm/code_080A3BD0.s.obj(.text);
        src/sub_080A554C.c.obj(.text);
        asm/code_080A5574.s.obj(.text);
        asm/playerItem/playerItemSword.s.obj(.text);
        asm/code_080A7C00.s.obj(.text);
        asm/projectile/projectile0.s.obj(.text);
        asm/projectile/projectile1.s.obj(.text);
        asm/projectile/projectile2.s.obj(.text);
        asm/projectile/projectile3.s.obj(.text);
        asm/projectile/projectile4.s.obj(.text);
        asm/projectile/projectile5.s.obj(.text);
        asm/projectile/projectile6.s.obj(.text);
        asm/projectile/projectile7.s.obj(.text);
        asm/projectile/projectile8.s.obj(.text);
        asm/projectile/projectile9.s.obj(.text);
        asm/projectile/projectileA.s.obj(.text);
        asm/projectile/projectileB.s.obj(.text);
        asm/projectile/projectileC.s.obj(.text);
        asm/projectile/projectileD.s.obj(.text);
        asm/projectile/projectileE.s.obj(.text);
        asm/projectile/projectileF.s.obj(.text);
        asm/projectile/projectile10.s.obj(.text);
        asm/projectile/projectile11.s.obj(.text);
        asm/projectile/projectile12.s.obj(.text);
        asm/projectile/projectile13.s.obj(.text);
        asm/projectile/projectile14.s.obj(.text);
        asm/projectile/projectile15.s.obj(.text);
        asm/projectile/projectile16.s.obj(.text);
        asm/projectile/projectile17.s.obj(.text);
        asm/projectile/projectile18.s.obj(.text);
        asm/projectile/projectile19.s.obj(.text);
        asm/projectile/projectile1A.s.obj(.text);
        asm/projectile/projectile1B.s.obj(.text);
        asm/projectile/projectile1C.s.obj(.text);
        asm/projectile/projectile1D.s.obj(.text);
        asm/projectile/projectile1E.s.obj(.text);
        asm/projectile/projectile1F.s.obj(.text);
        asm/projectile/projectile20.s.obj(.text);
        asm/projectile/projectile21.s.obj(.text);
        asm/projectile/projectile22.s.obj(.text);
        asm/projectile/projectile23.s.obj(.text);
        asm/projectile/projectile24.s.obj(.text);
        asm/playerItem/playerItem10.s.obj(.text);
        asm/playerItem/playerItem13.s.obj(.text);
        src/intro.c.obj(.text);
        asm/sub_080AD8F0.s.obj(.text);
        asm/code_080AD90C.s.obj(.text);
        asm/playerItem/playerItemGustJar.s.obj(.text);
        asm/code_080ADD30.s.obj(.text);
        /* library functions */
        asm/m4a_asm.s.obj(.text);
        src/gba/m4a.c.obj(.text);
        asm/libagbsyscall.s.obj(.text);
        src/eeprom.c.obj(.text);
        *libc.a:memcpy.o(.text);

        /* handwritten assembly in arm mode */
        asm/intr.s.obj(.text);
        /* data */
        data/data_080B2A70.s.obj(.rodata);
        src/playerItem.c.obj(.rodata);
        src/object.c.obj(.rodata);
        src/manager.c.obj(.rodata);
        src/npc.c.obj(.rodata);
        data/data_080B3740.s.obj(.rodata);
        data/const/playerItem/playerItem11.s.obj(.rodata);
        data/const/playerItem/playerItemBow.s.obj(.rodata);
        data/data_080B3E70.s.obj(.rodata);
        data/const/playerItem/playerItemSwordBeam.s.obj(.rodata);
        data/data_080B4410.s.obj(.rodata);
        data/const/playerItem/playerItemBomb.s.obj(.rodata);
        data/const/playerItem/playerItem3.s.obj(.rodata);
        data/const/playerItem/playerItemC.s.obj(.rodata);
        data/const/playerItem/playerItemSwordSpin.s.obj(.rodata);
        data/data_080B7910.s.obj(.rodata);
        data/const/playerItem/playerItemCellOverwriteSet.s.obj(.rodata);
        data/data_080B7B74.s.obj(.rodata);
        src/coord.c.obj(.rodata);
        data/data_080C93E0.s.obj(.rodata);
        src/enemy/octorok.c.obj(.rodata);
        data/animations/enemy/octorok.s.obj(.rodata);
        src/enemy/chuchu.c.obj(.rodata);
        data/animations/enemy/chuchu.s.obj(.rodata);
        src/enemy/leever.c.obj(.rodata);
        data/animations/enemy/leever.s.obj(.rodata);
        src/enemy/peahat.c.obj(.rodata);
        data/animations/enemy/peahat.s.obj(.rodata);
        src/enemy/rollobite.c.obj(.rodata);
        data/animations/enemy/rollobite.s.obj(.rodata);
        src/enemy/darkNut.c.obj(.rodata);
        data/animations/enemy/darkNut.s.obj(.rodata);
        src/enemy/hangingSeed.c.obj(.rodata);
        src/enemy/beetle.c.obj(.rodata);
        data/animations/enemy/beetle.s.obj(.rodata);
        src/enemy/keese.c.obj(.rodata);
        data/animations/enemy/keese.s.obj(.rodata);
        src/enemy/doorMimic.c.obj(.rodata);
        data/animations/enemy/doorMimic.s.obj(.rodata);
        src/enemy/rockChuchu.c.obj(.rodata);
        data/animations/enemy/rockChuchu.s.obj(.rodata);
        src/enemy/spinyChuchu.c.obj(.rodata);
        data/animations/enemy/spinyChuchu.s.obj(.rodata);
        src/enemy/cuccoChickAggr.c.obj(.rodata);
        src/enemy/moldorm.c.obj(.rodata);
        src/enemy/enemyE.c.obj(.rodata);
        data/animations/enemy/enemyE.s.obj(.rodata);
        src/enemy/moldworm.c.obj(.rodata);
        data/animations/enemy/moldworm.s.obj(.rodata);
        src/enemy/sluggula.c.obj(.rodata);
        data/animations/enemy/sluggula.s.obj(.rodata);
        src/enemy/pesto.c.obj(.rodata);
        data/animations/enemy/pesto.s.obj(.rodata);
        src/enemy/puffstool.c.obj(.rodata);
        data/animations/enemy/puffstool.s.obj(.rodata);
        src/enemy/chuchuBoss.c.obj(.rodata);
        data/animations/enemy/chuchuBoss.s.obj(.rodata);
        src/enemy/likeLike.c.obj(.rodata);
        data/animations/enemy/likeLike.s.obj(.rodata);
        src/enemy/spearMoblin.c.obj(.rodata);
        data/animations/enemy/spearMoblin.s.obj(.rodata);
        src/enemy/businessScrub.c.obj(.rodata);
        data/animations/enemy/businessScrub.s.obj(.rodata);
        src/enemy/rupeeLike.c.obj(.rodata);
        data/animations/enemy/rupeeLike.s.obj(.rodata);
        src/enemy/madderpillar.c.obj(.rodata);
        data/animations/enemy/madderpillar.s.obj(.rodata);
        src/enemy/waterDrop.c.obj(.rodata);
        data/animations/enemy/waterDrop.s.obj(.rodata);
        src/enemy/wallMaster.c.obj(.rodata);
        data/animations/enemy/wallMaster.s.obj(.rodata);
        src/enemy/bombPeahat.c.obj(.rodata);
        data/animations/enemy/bombPeahat.s.obj(.rodata);
        src/enemy/spark.c.obj(.rodata);
        data/animations/enemy/spark.s.obj(.rodata);
        src/enemy/chaser.c.obj(.rodata);
        data/animations/enemy/chaser.s.obj(.rodata);
        src/enemy/spikedBeetle.c.obj(.rodata);
        data/animations/enemy/spikedBeetle.s.obj(.rodata);
        src/enemy/sensorBladeTrap.c.obj(.rodata);
        src/enemy/helmasaur.c.obj(.rodata);
        data/animations/enemy/helmasaur.s.obj(.rodata);
        src/enemy/fallingBoulder.c.obj(.rodata);
        data/animations/enemy/fallingBoulder.s.obj(.rodata);
        src/enemy/bobomb.c.obj(.rodata);
        data/animations/enemy/bobomb.s.obj(.rodata);
        src/enemy/wallMaster2.c.obj(.rodata);
        data/const/enemy/gleerok.s.obj(.rodata);
        data/animations/enemy/gleerok.s.obj(.rodata);
        data/const/enemy/vaatiEyesMacro.s.obj(.rodata);
        data/animations/enemy/vaatiEyesMacro.s.obj(.rodata);
        data/const/enemy/tektite.s.obj(.rodata);
        data/animations/enemy/tektite.s.obj(.rodata);
        data/const/enemy/wizzrobeWind.s.obj(.rodata);
        data/animations/enemy/wizzrobeWind.s.obj(.rodata);
        data/const/enemy/wizzrobeFire.s.obj(.rodata);
        data/animations/enemy/wizzrobeFire.s.obj(.rodata);
        data/const/enemy/wizzrobeIce.s.obj(.rodata);
        data/animations/enemy/wizzrobeIce.s.obj(.rodata);
        data/const/enemy/armos.s.obj(.rodata);
        data/animations/enemy/armos.s.obj(.rodata);
        data/const/enemy/eyegore.s.obj(.rodata);
        data/animations/enemy/eyegore.s.obj(.rodata);
        data/const/enemy/rope.s.obj(.rodata);
        data/animations/enemy/rope.s.obj(.rodata);
        data/const/enemy/smallPesto.s.obj(.rodata);
        data/const/enemy/acroBandits.s.obj(.rodata);
        data/animations/enemy/acroBandits.s.obj(.rodata);
        data/const/enemy/keaton.s.obj(.rodata);
        data/animations/enemy/keaton.s.obj(.rodata);
        data/const/enemy/crow.s.obj(.rodata);
        data/animations/enemy/crow.s.obj(.rodata);
        data/const/enemy/mulldozer.s.obj(.rodata);
        data/animations/enemy/mulldozer.s.obj(.rodata);
        data/const/enemy/bombarossa.s.obj(.rodata);
        data/animations/enemy/bombarossa.s.obj(.rodata);
        data/const/enemy/wisp.s.obj(.rodata);
        data/animations/enemy/wisp.s.obj(.rodata);
        data/const/enemy/spinyBeetle.s.obj(.rodata);
        data/animations/enemy/spinyBeetle.s.obj(.rodata);
        data/const/enemy/mazaalHead.s.obj(.rodata);
        data/animations/enemy/mazaalHead.s.obj(.rodata);
        data/const/enemy/mazaalMacro.s.obj(.rodata);
        data/animations/enemy/mazaalMacro.s.obj(.rodata);
        data/const/enemy/mazaalHand.s.obj(.rodata);
        data/animations/enemy/mazaalHand.s.obj(.rodata);
        data/const/enemy/octorokBoss.s.obj(.rodata);
        data/animations/enemy/octorokBoss.s.obj(.rodata);
        data/const/enemy/flyingPot.s.obj(.rodata);
        data/const/enemy/gibdo.s.obj(.rodata);
        data/animations/enemy/gibdo.s.obj(.rodata);
        data/const/enemy/octorokGolden.s.obj(.rodata);
        data/const/enemy/tektiteGolden.s.obj(.rodata);
        data/const/enemy/ropeGolden.s.obj(.rodata);
        data/const/enemy/cloudPiranha.s.obj(.rodata);
        data/animations/enemy/cloudPiranha.s.obj(.rodata);
        data/const/enemy/scissorsBeetle.s.obj(.rodata);
        data/animations/enemy/scissorsBeetle.s.obj(.rodata);
        data/const/enemy/cuccoAggr.s.obj(.rodata);
        data/animations/enemy/cuccoAggr.s.obj(.rodata);
        data/const/enemy/stalfos.s.obj(.rodata);
        data/animations/enemy/stalfos.s.obj(.rodata);
        data/const/enemy/flyingSkull.s.obj(.rodata);
        data/animations/enemy/flyingSkull.s.obj(.rodata);
        data/const/enemy/mazaalBracelet.s.obj(.rodata);
        data/animations/enemy/mazaalBracelet.s.obj(.rodata);
        data/const/enemy/takkuri.s.obj(.rodata);
        data/const/enemy/bowMoblin.s.obj(.rodata);
        data/animations/enemy/bowMoblin.s.obj(.rodata);        src/enemy/lakitu.c.obj(.rodata);
        data/animations/enemy/lakitu.s.obj(.rodata);
        src/enemy/lakituCloud.c.obj(.rodata);
        data/const/enemy/enemy49.s.obj(.rodata);
        data/const/enemy/vaatiRebornEnemy.s.obj(.rodata);
        data/animations/enemy/vaatiRebornEnemy.s.obj(.rodata);
        data/const/enemy/vaatiProjectile.s.obj(.rodata);
        data/animations/enemy/vaatiProjectile.s.obj(.rodata);
        data/const/enemy/ballChainSoldier.s.obj(.rodata);
        data/animations/enemy/ballChainSoldier.s.obj(.rodata);
        data/const/enemy/enemy4D.s.obj(.rodata);
        data/const/enemy/ghini.s.obj(.rodata);
        data/animations/enemy/ghini.s.obj(.rodata);
        data/const/enemy/vaatiTransfigured.s.obj(.rodata);
        data/animations/enemy/vaatiTransfigured.s.obj(.rodata);
        data/const/enemy/enemy50.s.obj(.rodata);
        data/const/enemy/vaatiWrath.s.obj(.rodata);
        data/animations/enemy/vaatiWrath.s.obj(.rodata);
        data/const/enemy/vaatiArm.s.obj(.rodata);
        data/animations/enemy/vaatiArm.s.obj(.rodata);
        data/const/enemy/dust.s.obj(.rodata);
        data/const/enemy/vaatiBall.s.obj(.rodata);
        data/animations/enemy/vaatiBall.s.obj(.rodata);
        data/const/enemy/slime.s.obj(.rodata);
        data/animations/enemy/slime.s.obj(.rodata);
        data/const/enemy/miniSlime.s.obj(.rodata);
        data/const/enemy/fireballGuy.s.obj(.rodata);
        data/animations/enemy/fireballGuy.s.obj(.rodata);
        data/const/enemy/miniFireballGuy.s.obj(.rodata);
        data/const/enemy/enemy5A.s.obj(.rodata);
        data/animations/enemy/enemy5A.s.obj(.rodata);
        data/const/enemy/businessScrubPrologue.s.obj(.rodata);
        data/const/enemy/gyorgFemale.s.obj(.rodata);
        src/enemy/gyorgMale.c.obj(.rodata);
        data/animations/enemy/gyorgMale.s.obj(.rodata);
        data/const/enemy/curtain.s.obj(.rodata);
        data/animations/enemy/curtain.s.obj(.rodata);
        data/const/enemy/enemy5F.s.obj(.rodata);
        data/animations/enemy/enemy5F.s.obj(.rodata);
        data/const/enemy/gyorgChild.s.obj(.rodata);
        data/animations/enemy/gyorgChild.s.obj(.rodata);
        data/const/enemy/gyorgFemaleEye.s.obj(.rodata);
        data/animations/enemy/gyorgFemaleEye.s.obj(.rodata);
        data/const/enemy/enemy62.s.obj(.rodata);
        data/animations/enemy/enemy62.s.obj(.rodata);
        data/const/enemy/gyorgFemaleMouth.s.obj(.rodata);
        data/animations/enemy/gyorgFemaleMouth.s.obj(.rodata);
        data/const/enemy/enemy64.s.obj(.rodata);
        data/const/enemy/treeItem.s.obj(.rodata);
        data/const/enemy/enemy66.s.obj(.rodata);
        data/const/code_08049D30.s.obj(.rodata);
        src/enemy.c.obj(.rodata);
        data/data_080D3D94.s.obj(.rodata);
        data/entity_headers.s.obj(.rodata);
        data/data_080D5360.s.obj(.rodata);
        src/fileScreen.c.obj(.rodata);
        data/data_080FC8A4.s.obj(.rodata);
        data/const/playerItem/playerItemLantern.s.obj(.rodata);
        data/data_080FEEB8.s.obj(.rodata);
        src/main.c.obj(.rodata);
        data/tileset_headers.s.obj(.rodata);
        data/metatile_headers.s.obj(.rodata);
        data/map_headers.s.obj(.rodata);
        src/textbox.c.obj(.rodata);
        data/data_08107BC8.s.obj(.rodata);
        data/const/manager/manager1.s.obj(.rodata);
        data/const/manager/manager3.s.obj(.rodata);
        data/const/manager/manager4.s.obj(.rodata);
        src/manager/manager5.c.obj(.rodata);
        src/manager/manager7.c.obj(.rodata);
    . = ALIGN(4);
        src/manager/manager9.c.obj(.rodata);
        src/manager/managerA.c.obj(.rodata);
        src/manager/managerB.c.obj(.rodata);
        src/manager/managerC.c.obj(.rodata);
        data/const/manager/managerD.s.obj(.rodata);
        data/const/manager/managerF.s.obj(.rodata);
        data/const/manager/manager10.s.obj(.rodata);
        data/const/manager/manager12.s.obj(.rodata);
        data/const/manager/manager13.s.obj(.rodata);
        data/const/manager/manager14.s.obj(.rodata);
        data/const/manager/manager15.s.obj(.rodata);
        data/const/manager/manager17.s.obj(.rodata);
        data/const/manager/manager18.s.obj(.rodata);
        data/const/manager/manager1A.s.obj(.rodata);
        data/const/manager/manager1B.s.obj(.rodata);
        data/const/manager/manager1C.s.obj(.rodata);
        data/const/manager/manager1D.s.obj(.rodata);
        src/manager/manager1E.c.obj(.rodata);
        data/const/manager/manager1F.s.obj(.rodata);
        data/const/manager/manager22.s.obj(.rodata);
        data/const/manager/manager23.s.obj(.rodata);
        data/const/manager/manager24.s.obj(.rodata);
        src/manager/manager26.c.obj(.rodata);
        src/manager/manager27.c.obj(.rodata);
        src/manager/manager28.c.obj(.rodata);
        data/const/manager/manager2B.s.obj(.rodata);
        data/const/manager/manager2E.s.obj(.rodata);
        data/const/manager/manager31.s.obj(.rodata);
        data/const/manager/manager32.s.obj(.rodata);
        data/const/manager/manager34.s.obj(.rodata);
        data/const/manager/manager35.s.obj(.rodata);
        data/const/manager/manager36.s.obj(.rodata);
        data/const/manager/manager37.s.obj(.rodata);
        data/const/manager/manager38.s.obj(.rodata);
        data/const/manager/manager39.s.obj(.rodata);
        data/data_08108E6C.s.obj(.rodata);
        data/const/playerItem/playerItem14.s.obj(.rodata);
        data/animations/npc/gentari.s.obj(.rodata);
        data/const/npc/festari.s.obj(.rodata);
        data/animations/npc/festari.s.obj(.rodata);
        data/const/npc/forestMinish.s.obj(.rodata);
        data/animations/npc/forestMinish.s.obj(.rodata);
        data/const/npc/postman.s.obj(.rodata);
        data/animations/npc/postman.s.obj(.rodata);
        data/const/npc/npc5.s.obj(.rodata);
        data/animations/npc/npc5.s.obj(.rodata);
        data/const/npc/townsperson.s.obj(.rodata);
        data/animations/npc/townsperson.s.obj(.rodata);
        data/const/npc/kid.s.obj(.rodata);
        data/animations/npc/kid.s.obj(.rodata);
        data/const/npc/npc9.s.obj(.rodata);
        data/animations/npc/npc9.s.obj(.rodata);
        data/const/npc/stamp.s.obj(.rodata);
        data/animations/npc/stamp.s.obj(.rodata);
        data/const/npc/marcy.s.obj(.rodata);
        data/animations/npc/marcy.s.obj(.rodata);
        data/const/npc/wheaton.s.obj(.rodata);
        data/animations/npc/wheaton.s.obj(.rodata);
        data/const/npc/pita.s.obj(.rodata);
        data/animations/npc/pita.s.obj(.rodata);
        data/const/npc/minishEzlo.s.obj(.rodata);
        data/animations/npc/minishEzlo.s.obj(.rodata);
        data/const/npc/mailbox.s.obj(.rodata);
        data/animations/npc/mailbox.s.obj(.rodata);
        data/const/npc/beedle.s.obj(.rodata);
        data/animations/npc/beedle.s.obj(.rodata);
        data/const/npc/brocco.s.obj(.rodata);
        data/animations/npc/brocco.s.obj(.rodata);
        data/const/npc/sittingPerson.s.obj(.rodata);
        data/animations/npc/sittingPerson.s.obj(.rodata);
        data/const/npc/pina.s.obj(.rodata);
        data/animations/npc/pina.s.obj(.rodata);
        data/const/npc/guard.s.obj(.rodata);
        data/animations/npc/guard.s.obj(.rodata);
        data/const/npc/guardWithSpear.s.obj(.rodata);
        data/animations/npc/guardWithSpear.s.obj(.rodata);
        data/const/npc/maid.s.obj(.rodata);
        data/animations/npc/maid.s.obj(.rodata);
        data/animations/npc/din.s.obj(.rodata);
        data/animations/npc/nayru.s.obj(.rodata);
        data/animations/npc/farore.s.obj(.rodata);
        data/const/npc/sturgeon.s.obj(.rodata);
        data/animations/npc/sturgeon.s.obj(.rodata);
        data/const/npc/tingleSiblings.s.obj(.rodata);
        data/animations/npc/tingleSiblings.s.obj(.rodata);
        data/const/npc/stockwell.s.obj(.rodata);
        data/animations/npc/stockwell.s.obj(.rodata);
        data/const/npc/talon.s.obj(.rodata);
        data/animations/npc/talon.s.obj(.rodata);
        data/const/npc/malon.s.obj(.rodata);
        data/animations/npc/malon.s.obj(.rodata);
        data/const/npc/epona.s.obj(.rodata);
        data/animations/npc/epona.s.obj(.rodata);
        data/const/npc/milkCart.s.obj(.rodata);
        data/animations/npc/milkCart.s.obj(.rodata);
        data/const/npc/ghostBrothers.s.obj(.rodata);
        data/animations/npc/ghostBrothers.s.obj(.rodata);
        data/const/npc/smith.s.obj(.rodata);
        data/animations/npc/smith.s.obj(.rodata);
        data/const/npc/npc23.s.obj(.rodata);
        data/const/npc/kingDaltus.s.obj(.rodata);
        data/animations/npc/kingDaltus.s.obj(.rodata);
        data/const/npc/ministerPotho.s.obj(.rodata);
        data/animations/npc/ministerPotho.s.obj(.rodata);
        data/const/npc/npc26.s.obj(.rodata);
        data/animations/npc/npc26.s.obj(.rodata);
        data/const/npc/vaati.s.obj(.rodata);
        data/animations/npc/vaati.s.obj(.rodata);
        data/const/npc/zelda.s.obj(.rodata);
        data/const/npc/mutoh.s.obj(.rodata);
        data/animations/npc/mutoh.s.obj(.rodata);
        data/const/npc/carpenter.s.obj(.rodata);
        data/animations/npc/carpenter.s.obj(.rodata);
        data/const/npc/castorWildsStatue.s.obj(.rodata);
        data/animations/npc/castorWildsStatue.s.obj(.rodata);
        data/const/npc/cat.s.obj(.rodata);
        data/animations/npc/cat.s.obj(.rodata);
        data/const/npc/mountainMinish.s.obj(.rodata);
        data/animations/npc/mountainMinish.s.obj(.rodata);
        data/const/npc/melari.s.obj(.rodata);
        data/animations/npc/melari.s.obj(.rodata);
        data/const/npc/bladeBrothers.s.obj(.rodata);
        data/animations/npc/bladeBrothers.s.obj(.rodata);
        data/const/npc/cow.s.obj(.rodata);
        data/animations/npc/cow.s.obj(.rodata);
        data/const/npc/goron.s.obj(.rodata);
        data/animations/npc/goron.s.obj(.rodata);
        data/const/npc/goronMerchant.s.obj(.rodata);
        data/animations/npc/goronMerchant.s.obj(.rodata);
        data/const/npc/gorman.s.obj(.rodata);
        data/animations/npc/gorman.s.obj(.rodata);
        data/const/npc/dog.s.obj(.rodata);
        data/animations/npc/dog.s.obj(.rodata);
        data/const/npc/syrup.s.obj(.rodata);
        data/animations/npc/syrup.s.obj(.rodata);
        data/const/npc/rem.s.obj(.rodata);
        data/animations/npc/rem.s.obj(.rodata);
        data/const/npc/townMinish.s.obj(.rodata);
        data/animations/npc/townMinish.s.obj(.rodata);
        data/const/npc/librari.s.obj(.rodata);
        data/animations/npc/librari.s.obj(.rodata);
        data/const/npc/percy.s.obj(.rodata);
        data/animations/npc/percy.s.obj(.rodata);
        data/const/npc/vaatiReborn.s.obj(.rodata);
        data/animations/npc/vaatiReborn.s.obj(.rodata);
        data/const/npc/moblinLady.s.obj(.rodata);
        data/animations/npc/moblinLady.s.obj(.rodata);
        data/const/npc/librarians.s.obj(.rodata);
        data/animations/npc/librarians.s.obj(.rodata);
        data/const/npc/farmers.s.obj(.rodata);
        data/animations/npc/farmers.s.obj(.rodata);
        data/animations/npc/carlov.s.obj(.rodata);
        data/const/npc/dampe.s.obj(.rodata);
        data/animations/npc/dampe.s.obj(.rodata);
        data/const/npc/drLeft.s.obj(.rodata);
        data/animations/npc/drLeft.s.obj(.rodata);
        data/animations/npc/kingGustav.s.obj(.rodata);
        data/animations/npc/gina.s.obj(.rodata);
        data/animations/npc/simon.s.obj(.rodata);
        data/animations/npc/anju.s.obj(.rodata);
        data/const/npc/mama.s.obj(.rodata);
        data/animations/npc/mama.s.obj(.rodata);
        data/animations/npc/emma.s.obj(.rodata);
        data/const/npc/teachers.s.obj(.rodata);
        data/animations/npc/teachers.s.obj(.rodata);
        data/const/npc/windTribespeople.s.obj(.rodata);
        data/animations/npc/windTribespeople.s.obj(.rodata);
        data/const/npc/gregal.s.obj(.rodata);
        data/animations/npc/gregal.s.obj(.rodata);
        data/const/npc/mayorHagen.s.obj(.rodata);
        data/animations/npc/mayorHagen.s.obj(.rodata);
        data/const/npc/bigGoron.s.obj(.rodata);
        src/npc/ezloCap.c.obj(.rodata);
        data/animations/npc/npc4f.s.obj(.rodata);
        data/const/npc/clothesRack.s.obj(.rodata);
        data/animations/npc/clothesRack.s.obj(.rodata);
        data/const/npc/picolyteBottle.s.obj(.rodata);
        data/const/npc/smallTownMinish.s.obj(.rodata);
        data/animations/npc/smallTownMinish.s.obj(.rodata);
        data/const/npc/hurdyGurdyMan.s.obj(.rodata);
        data/animations/npc/hurdyGurdyMan.s.obj(.rodata);
        data/const/npc/cucco.s.obj(.rodata);
        data/const/npc/cuccoChick.s.obj(.rodata);
        data/const/npc/phonograph.s.obj(.rodata);
        data/const/npc/npc58.s.obj(.rodata);
        data/data_081146D0.s.obj(.rodata);
        data/const/playerItem/playerItem12.s.obj(.rodata);
        data/const/playerItem/playerItemPacciCane.s.obj(.rodata);
        src/player.c.obj(.rodata);
        data/data_0811B9E0.s.obj(.rodata);
        src/item.c.obj(.rodata);
        data/const/item/itemSword.s.obj(.rodata);
        data/const/item/itemLantern.s.obj(.rodata);
        data/const/item/itemBoomerang.s.obj(.rodata);
        data/const/item/itemBow.s.obj(.rodata);
        data/const/item/itemBomb.s.obj(.rodata);
        data/const/item/itemTryPickupObject.s.obj(.rodata);
        data/const/item/itemPegasusBoots.s.obj(.rodata);
        data/const/item/itemOcarina.s.obj(.rodata);
        data/const/item/itemPacciCane.s.obj(.rodata);
        data/const/item/itemShield.s.obj(.rodata);
        data/const/item/itemGustJar.s.obj(.rodata);
        data/const/item/itemMoleMitts.s.obj(.rodata);
        data/const/item/itemJarEmpty.s.obj(.rodata);
        data/data_0811BE38.s.obj(.rodata);
        data/room_headers.s.obj(.rodata);
        src/save.c.obj(.rodata);
        data/data_0811E454.s.obj(.rodata);
        src/script.c.obj(.rodata);
        data/data_0811E750.s.obj(.rodata);
        data/const/object/itemOnGround.s.obj(.rodata);
        data/const/object/deathFx.s.obj(.rodata);
        data/animations/object/deathFx.s.obj(.rodata);
        data/const/object/itemForSale.s.obj(.rodata);
        data/const/object/button.s.obj(.rodata);
        data/const/object/object4.s.obj(.rodata);
        data/animations/object/object4.s.obj(.rodata);
        data/const/object/pot.s.obj(.rodata);
        data/animations/object/pot.s.obj(.rodata);
        data/const/object/object6.s.obj(.rodata);
        data/animations/object/object6.s.obj(.rodata);
        data/const/object/blockPushed.s.obj(.rodata);
        data/const/object/lockedDoor.s.obj(.rodata);
        data/const/object/object9.s.obj(.rodata);
        data/animations/object/object9.s.obj(.rodata);
        data/const/object/objectB.s.obj(.rodata);
        data/const/object/chestSpawner.s.obj(.rodata);
        data/animations/object/chestSpawner.s.obj(.rodata);
        data/const/object/objectD.s.obj(.rodata);
        data/animations/object/objectD.s.obj(.rodata);
        data/const/object/specialFx.s.obj(.rodata);
        data/animations/object/specialFx.s.obj(.rodata);
        data/const/object/object10.s.obj(.rodata);
        data/const/object/object11.s.obj(.rodata);
        data/const/object/object12.s.obj(.rodata);
        data/const/object/railtrack.s.obj(.rodata);
        data/animations/object/railtrack.s.obj(.rodata);
        data/const/object/lilypadLarge.s.obj(.rodata);
        data/const/object/object15.s.obj(.rodata);
        data/const/object/floatingPlatform.s.obj(.rodata);
        data/const/object/object17.s.obj(.rodata);
        data/const/object/evilSpirit.s.obj(.rodata);
        data/const/object/houseDoorExterior.s.obj(.rodata);
        data/const/object/object1A.s.obj(.rodata);
        src/object/greatFairy.c.obj(.rodata);
        data/animations/npc/greatFairy.s.obj(.rodata);
data/const/object/object1D.s.obj(.rodata);
        data/const/object/object1E.s.obj(.rodata);
        data/animations/object/object1E.s.obj(.rodata);
        data/const/object/object1F.s.obj(.rodata);
        data/const/object/object20.s.obj(.rodata);
        data/animations/object/object20.s.obj(.rodata);
        data/const/object/object21.s.obj(.rodata);
        data/const/object/figurineDevice.s.obj(.rodata);
        data/animations/object/figurineDevice.s.obj(.rodata);
        data/const/object/eyeSwitch.s.obj(.rodata);
        data/animations/object/eyeSwitch.s.obj(.rodata);
        data/const/object/object24.s.obj(.rodata);
        data/animations/object/object24.s.obj(.rodata);
        data/const/object/bigBarrel.s.obj(.rodata);
        data/animations/object/bigBarrel.s.obj(.rodata);
        data/const/object/object26.s.obj(.rodata);
        data/const/object/pushableStatue.s.obj(.rodata);
        data/animations/object/pushableStatue.s.obj(.rodata);
        data/const/object/object29.s.obj(.rodata);
        data/animations/object/object29.s.obj(.rodata);
        data/const/object/object2A.s.obj(.rodata);
        data/animations/object/object2A.s.obj(.rodata);
        data/const/object/beanstalk.s.obj(.rodata);
        data/animations/object/beanstalk.s.obj(.rodata);
        data/const/object/smoke.s.obj(.rodata);
        data/const/object/pushableRock.s.obj(.rodata);
        data/animations/object/pushableRock.s.obj(.rodata);
        data/const/object/hittableLever.s.obj(.rodata);
        data/const/object/object30.s.obj(.rodata);
        data/const/object/object31.s.obj(.rodata);
        data/const/object/pullableMushroom.s.obj(.rodata);
        data/animations/object/pullableMushroom.s.obj(.rodata);
        data/const/object/bollard.s.obj(.rodata);
        data/animations/object/bollard.s.obj(.rodata);
        data/const/object/warpPoint.s.obj(.rodata);
        data/animations/object/warpPoint.s.obj(.rodata);
        data/const/object/object35.s.obj(.rodata);
        data/animations/object/object35.s.obj(.rodata);
        data/const/object/object36.s.obj(.rodata);
        data/const/object/object37.s.obj(.rodata);
        data/const/object/jarPortal.s.obj(.rodata);
        data/animations/object/jarPortal.s.obj(.rodata);
        data/const/object/bossDoor.s.obj(.rodata);
        data/animations/object/bossDoor.s.obj(.rodata);
        data/const/object/object3A.s.obj(.rodata);
        data/const/object/macroMushroomStalks.s.obj(.rodata);
        data/const/object/object75.s.obj(.rodata);
        data/const/object/object76.s.obj(.rodata);
        data/const/object/macroPlayer.s.obj(.rodata);
        data/const/object/object3D.s.obj(.rodata);
        data/const/object/object3E.s.obj(.rodata);
        data/const/object/giantLeaf.s.obj(.rodata);
        data/const/object/fairy.s.obj(.rodata);
        data/const/object/object42.s.obj(.rodata);
        data/const/object/object43.s.obj(.rodata);
        data/animations/object/object43.s.obj(.rodata);
        data/const/object/object44.s.obj(.rodata);
        data/animations/object/object44.s.obj(.rodata);
        data/const/object/object45.s.obj(.rodata);
        data/animations/object/object45.s.obj(.rodata);
        data/const/object/giantBookLadder.s.obj(.rodata);
        src/object/heartContainer.c.obj(.rodata);
        data/const/object/heartContainer.s.obj(.rodata);
        data/const/object/fileScreenObjects.s.obj(.rodata);
        data/animations/object/fileScreenObjects.s.obj(.rodata);
        data/const/object/object49.s.obj(.rodata);
        data/const/object/backgroundCloud.s.obj(.rodata);
        data/const/object/object4B.s.obj(.rodata);
        data/const/object/pushableFurniture.s.obj(.rodata);
        data/const/object/furniture.s.obj(.rodata);
        data/animations/object/furniture.s.obj(.rodata);
        data/const/object/minishSizedEntrance.s.obj(.rodata);
        data/animations/object/minishSizedEntrance.s.obj(.rodata);
        data/const/object/object51.s.obj(.rodata);
        data/const/object/object53.s.obj(.rodata);
        data/const/object/pullableLever.s.obj(.rodata);
        data/animations/object/pullableLever.s.obj(.rodata);
        data/const/object/minecart.s.obj(.rodata);
        data/animations/object/minecart.s.obj(.rodata);
        data/const/object/thoughtBubble.s.obj(.rodata);
        data/animations/object/thoughtBubble.s.obj(.rodata);
        data/const/object/hiddenLadderDown.s.obj(.rodata);
        data/const/object/gentariCurtains.s.obj(.rodata);
        data/animations/object/gentariCurtains.s.obj(.rodata);
        data/const/object/lavaPlatform.s.obj(.rodata);
        data/animations/object/lavaPlatform.s.obj(.rodata);
        data/const/object/object5A.s.obj(.rodata);
        data/const/object/object5B.s.obj(.rodata);
        data/const/object/mask.s.obj(.rodata);
        data/const/object/houseDoorInterior.s.obj(.rodata);
        data/const/object/whirlwind.s.obj(.rodata);
        data/animations/object/whirlwind.s.obj(.rodata);
        data/const/object/objectBlockingStairs.s.obj(.rodata);
        data/const/object/swordsmanNewsletter.s.obj(.rodata);
        data/const/object/object61.s.obj(.rodata);
        data/const/object/giantTwig.s.obj(.rodata);
        data/const/object/object63.s.obj(.rodata);
        data/const/object/object64.s.obj(.rodata);
        data/animations/object/object64.s.obj(.rodata);
        data/const/object/ladderHoleInBookshelf.s.obj(.rodata);
        data/const/object/object67.s.obj(.rodata);
        data/const/object/object68.s.obj(.rodata);
        data/const/object/object6A.s.obj(.rodata);
        data/animations/object/object6A.s.obj(.rodata);
        data/const/object/crenalBeanSprout.s.obj(.rodata);
        data/animations/object/crenalBeanSprout.s.obj(.rodata);
        data/const/object/minecartDoor.s.obj(.rodata);
        data/const/object/objectOnPillar.s.obj(.rodata);
        data/const/object/mineralWaterSource.s.obj(.rodata);
        data/const/object/object70.s.obj(.rodata);
        data/const/object/pushableGrave.s.obj(.rodata);
        data/const/object/object72.s.obj(.rodata);
        data/const/object/lilypadSmall.s.obj(.rodata);
        data/const/object/object74.s.obj(.rodata);
        data/const/object/bell.s.obj(.rodata);
        data/const/object/macroDecorations.s.obj(.rodata);
        data/const/object/object79.s.obj(.rodata);
        data/animations/object/object79.s.obj(.rodata);
        data/const/object/steam.s.obj(.rodata);
        data/const/object/pushableLever.s.obj(.rodata);
        data/animations/object/pushableLever.s.obj(.rodata);
        data/const/object/macroShoes.s.obj(.rodata);
        data/const/object/objectOnSpinyBeetle.s.obj(.rodata);
        data/const/object/picoBloom.s.obj(.rodata);
        data/animations/object/picoBloom.s.obj(.rodata);
        data/const/object/object80.s.obj(.rodata);
        data/const/object/object81.s.obj(.rodata);
        data/const/object/bigVortex.s.obj(.rodata);
        data/animations/object/bigVortex.s.obj(.rodata);
        data/const/object/bigPushableLever.s.obj(.rodata);
        data/animations/object/bigPushableLever.s.obj(.rodata);
        data/const/object/smallIceBlock.s.obj(.rodata);
        data/animations/object/smallIceBlock.s.obj(.rodata);
        data/const/object/bigIceBlock.s.obj(.rodata);
        data/animations/object/bigIceBlock.s.obj(.rodata);
        data/const/object/object86.s.obj(.rodata);
        data/animations/object/object86.s.obj(.rodata);
        data/const/object/object87.s.obj(.rodata);
        data/const/object/macroBook.s.obj(.rodata);
        data/animations/object/macroBook.s.obj(.rodata);
        data/const/object/object89.s.obj(.rodata);
        data/const/object/object8A.s.obj(.rodata);
        data/const/object/object8B.s.obj(.rodata);
        data/const/object/books.s.obj(.rodata);
        data/const/object/fireplace.s.obj(.rodata);
        data/const/object/object8E.s.obj(.rodata);
        data/const/object/frozenWaterElement.s.obj(.rodata);
        data/const/object/object90.s.obj(.rodata);
        data/const/object/object91.s.obj(.rodata);
        data/const/object/bakerOven.s.obj(.rodata);
        data/animations/object/bakerOven.s.obj(.rodata);
        data/const/object/object93.s.obj(.rodata);
        data/const/object/bird.s.obj(.rodata);
        data/animations/object/bird.s.obj(.rodata);
        data/const/object/object96.s.obj(.rodata);
        data/const/object/object97.s.obj(.rodata);
        data/const/object/object98.s.obj(.rodata);
        data/animations/object/object98.s.obj(.rodata);
        data/const/object/macroAcorn.s.obj(.rodata);
        data/const/object/object9B.s.obj(.rodata);
        data/animations/object/object9B.s.obj(.rodata);
        data/const/object/treeHidingPortal.s.obj(.rodata);
        data/const/object/lightableSwitch.s.obj(.rodata);
        data/const/object/fan.s.obj(.rodata);
        data/animations/object/fan.s.obj(.rodata);
        data/const/object/objectA0.s.obj(.rodata);
        data/animations/object/objectA0.s.obj(.rodata);
        data/const/object/palaceArchway.s.obj(.rodata);        src/object/objectA2.c.obj(.rodata);
        data/animations/object/objectA2.s.obj(.rodata);
        data/const/object/cloud.s.obj(.rodata);
        data/const/object/minishLight.s.obj(.rodata);
        data/const/object/objectA6.s.obj(.rodata);
        data/animations/object/objectA6.s.obj(.rodata);
        data/const/object/objectA8.s.obj(.rodata);
        data/const/object/objectA9.s.obj(.rodata);
        data/const/object/waterfallOpening.s.obj(.rodata);
        data/const/object/objectAB.s.obj(.rodata);
        data/animations/object/objectAB.s.obj(.rodata);
        data/const/object/fourElements.s.obj(.rodata);
        data/const/object/objectAD.s.obj(.rodata);
        data/const/object/objectAF.s.obj(.rodata);
        data/animations/object/objectAF.s.obj(.rodata);
        data/const/object/metalDoor.s.obj(.rodata);
        data/const/object/jailBars.s.obj(.rodata);
        data/animations/object/jailBars.s.obj(.rodata);
        data/animations/object/objectB2.s.obj(.rodata);
        data/const/object/objectB3.s.obj(.rodata);
        data/animations/object/objectB3.s.obj(.rodata);
        data/const/object/objectB4.s.obj(.rodata);
        data/animations/object/objectB4.s.obj(.rodata);
        data/const/object/well.s.obj(.rodata);
        data/const/object/windTribeTeleporter.s.obj(.rodata);
        data/const/object/objectB9.s.obj(.rodata);
        data/const/object/objectBA.s.obj(.rodata);
        data/animations/object/objectBA.s.obj(.rodata);
        data/const/object/windcrest.s.obj(.rodata);
        data/const/object/objectBD.s.obj(.rodata);
        data/const/object/pinwheel.s.obj(.rodata);
        data/animations/object/pinwheel.s.obj(.rodata);
        data/const/object/objectC1.s.obj(.rodata);
        data/data_08125104.s.obj(.rodata);
        data/const/playerItem/playerItemShield.s.obj(.rodata);
        data/const/playerItem/playerItem15.s.obj(.rodata);
        data/data_08127280.s.obj(.rodata);
        data/const/playerItem/playerItemSword.s.obj(.rodata);
        data/data_08129320.s.obj(.rodata);
        data/const/projectile/projectile0.s.obj(.rodata);
        data/const/projectile/projectile1.s.obj(.rodata);
        data/animations/projectile/projectile1.s.obj(.rodata);
        data/const/projectile/projectile2.s.obj(.rodata);
        data/animations/projectile/projectile2.s.obj(.rodata);
        data/const/projectile/projectile3.s.obj(.rodata);
        data/const/projectile/projectile4.s.obj(.rodata);
        data/const/projectile/projectile5.s.obj(.rodata);
        data/const/projectile/projectile6.s.obj(.rodata);
        data/animations/projectile/projectile6.s.obj(.rodata);
        data/const/projectile/projectile7.s.obj(.rodata);
        data/animations/projectile/projectile7.s.obj(.rodata);
        data/const/projectile/projectile8.s.obj(.rodata);
        data/animations/projectile/projectile8.s.obj(.rodata);
        data/const/projectile/projectile9.s.obj(.rodata);
        data/animations/projectile/projectile9.s.obj(.rodata);
        data/const/projectile/projectileA.s.obj(.rodata);
        data/const/projectile/projectileB.s.obj(.rodata);
        data/const/projectile/projectileC.s.obj(.rodata);
        data/const/projectile/projectileD.s.obj(.rodata);
        data/animations/projectile/projectileD.s.obj(.rodata);
        data/const/projectile/projectileE.s.obj(.rodata);
        data/animations/projectile/projectileE.s.obj(.rodata);
        data/const/projectile/projectileF.s.obj(.rodata);
        data/const/projectile/projectile10.s.obj(.rodata);
        data/const/projectile/projectile11.s.obj(.rodata);
        data/animations/projectile/projectile11.s.obj(.rodata);
        data/const/projectile/projectile12.s.obj(.rodata);
        data/animations/projectile/projectile12.s.obj(.rodata);
        data/const/projectile/projectile13.s.obj(.rodata);
        data/animations/projectile/projectile13.s.obj(.rodata);
        data/const/projectile/projectile14.s.obj(.rodata);
        data/const/projectile/projectile15.s.obj(.rodata);
        data/animations/projectile/projectile15.s.obj(.rodata);
        data/const/projectile/projectile16.s.obj(.rodata);
        data/animations/projectile/projectile16.s.obj(.rodata);
        data/const/projectile/projectile18.s.obj(.rodata);
        data/animations/projectile/projectile18.s.obj(.rodata);
        data/const/projectile/projectile19.s.obj(.rodata);
        data/const/projectile/projectile1A.s.obj(.rodata);
        data/const/projectile/projectile1B.s.obj(.rodata);
        data/animations/projectile/projectile1B.s.obj(.rodata);
        data/const/projectile/projectile1C.s.obj(.rodata);
        data/animations/projectile/projectile1C.s.obj(.rodata);
        data/const/projectile/projectile1D.s.obj(.rodata);
        data/const/projectile/projectile1E.s.obj(.rodata);
        data/animations/projectile/projectile1E.s.obj(.rodata);
        data/const/projectile/projectile1F.s.obj(.rodata);
        data/animations/projectile/projectile1F.s.obj(.rodata);
        data/const/projectile/projectile20.s.obj(.rodata);
        data/animations/projectile/projectile20.s.obj(.rodata);
        data/const/projectile/projectile21.s.obj(.rodata);
        data/const/projectile/projectile22.s.obj(.rodata);
        data/const/projectile/projectile23.s.obj(.rodata);
        data/animations/projectile/projectile23.s.obj(.rodata);
        data/const/projectile/projectile24.s.obj(.rodata);
        data/const/playerItem/playerItem10.s.obj(.rodata);
        data/data_0812AA88.s.obj(.rodata);
        data/const/playerItem/playerItem13.s.obj(.rodata);
        src/intro.c.obj(.rodata);
        data/data_081320FC.s.obj(.rodata);
        data/const/playerItem/playerItemGustJar.s.obj(.rodata);
        data/data_08132B30.s.obj(.rodata);
        data/strings.s.obj(.rodata);
        data/sprite_table.s.obj(.rodata);
        src/gba/m4a.c.obj(.rodata);
        data/data_089FC6C4.s.obj(.rodata);
        src/audio.c.obj(.rodata);
        data/data_08A127A1.s.obj(.rodata);
        data/sounds.s.obj(.rodata);
        src/eeprom.c.obj(.rodata);
    } >rom

    /* DWARF 2 sections */
    .debug_aranges  0 : { *(.debug_aranges) }
    .debug_pubnames 0 : { *(.debug_pubnames) }
    .debug_info     0 : { *(.debug_info) }
    .debug_abbrev   0 : { *(.debug_abbrev) }
    .debug_line     0 : { *(.debug_line) }
    .debug_frame    0 : { *(.debug_frame) }
    .debug_str      0 : { *(.debug_str) }
    .debug_loc      0 : { *(.debug_loc) }
    .debug_macinfo  0 : { *(.debug_macinfo) }

    /* Discard everything not specifically mentioned above. */
    /DISCARD/ :
    {
        *(*);
    }
}
